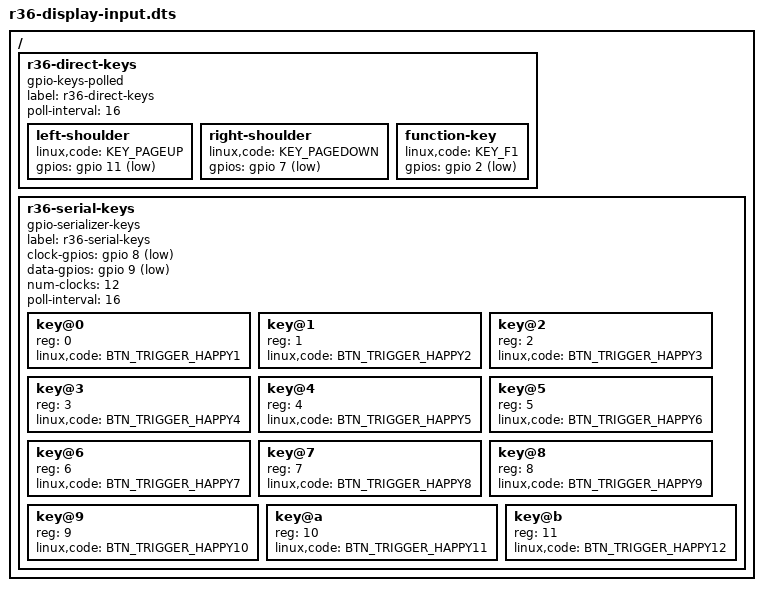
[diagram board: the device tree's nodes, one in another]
// SPDX-License-Identifier: GPL-2.0
#include "r36-display.dts"
#include <dt-bindings/gpio/gpio.h>
#include <dt-bindings/input/input.h>

/ {
    /* Poll-only inputs: no power/reboot/volume policy or output GPIO claims. */
    r36-direct-keys {
        compatible = "gpio-keys-polled";
        label = "r36-direct-keys";
        poll-interval = <16>;
        left-shoulder { linux,code = <KEY_PAGEUP>; gpios = <&gpio 11 GPIO_ACTIVE_LOW>; };
        right-shoulder { linux,code = <KEY_PAGEDOWN>; gpios = <&gpio 7 GPIO_ACTIVE_LOW>; };
        function-key { linux,code = <KEY_F1>; gpios = <&gpio 2 GPIO_ACTIVE_LOW>; };
    };
    r36-serial-keys {
        compatible = "gpio-serializer-keys";
        label = "r36-serial-keys";
        #address-cells = <1>;
        #size-cells = <0>;
        clock-gpios = <&gpio 8 GPIO_ACTIVE_LOW>;
        data-gpios = <&gpio 9 (GPIO_ACTIVE_LOW | GPIO_OPEN_DRAIN)>;
        num-clocks = <12>;
        poll-interval = <16>;
        /* Raw serial positions, not claimed physical labels. Calibrate each
         * physical button before translating these into the legacy UI bits. */
        key@0 { reg = <0>; linux,code = <BTN_TRIGGER_HAPPY1>; };
        key@1 { reg = <1>; linux,code = <BTN_TRIGGER_HAPPY2>; };
        key@2 { reg = <2>; linux,code = <BTN_TRIGGER_HAPPY3>; };
        key@3 { reg = <3>; linux,code = <BTN_TRIGGER_HAPPY4>; };
        key@4 { reg = <4>; linux,code = <BTN_TRIGGER_HAPPY5>; };
        key@5 { reg = <5>; linux,code = <BTN_TRIGGER_HAPPY6>; };
        key@6 { reg = <6>; linux,code = <BTN_TRIGGER_HAPPY7>; };
        key@7 { reg = <7>; linux,code = <BTN_TRIGGER_HAPPY8>; };
        key@8 { reg = <8>; linux,code = <BTN_TRIGGER_HAPPY9>; };
        key@9 { reg = <9>; linux,code = <BTN_TRIGGER_HAPPY10>; };
        key@a { reg = <10>; linux,code = <BTN_TRIGGER_HAPPY11>; };
        key@b { reg = <11>; linux,code = <BTN_TRIGGER_HAPPY12>; };
    };
};
